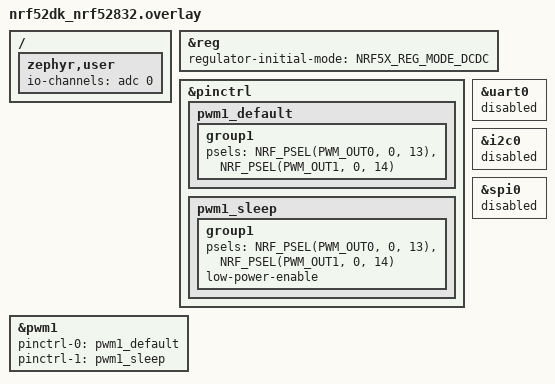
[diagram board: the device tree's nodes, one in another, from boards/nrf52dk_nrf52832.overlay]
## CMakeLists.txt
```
cmake_minimum_required(VERSION 3.20.0)

find_package(Zephyr REQUIRED HINTS $ENV{ZEPHYR_BASE})
project(yuitag)

set(YUITAG_CORE_DIR ${CMAKE_CURRENT_SOURCE_DIR}/../../YuiTagCore)

target_include_directories(app PRIVATE
    ${CMAKE_CURRENT_SOURCE_DIR}/src
    ${YUITAG_CORE_DIR}/include
    ${YUITAG_CORE_DIR}/lib
)

target_sources(app PRIVATE
    src/main.c
    src/app.c
    src/yuitag_platform.c
    src/yuitag_crypto.c
    src/yuitag_buzzer.c
    src/yuitag_ble.c
    src/yuitag_findmy.c
    ${YUITAG_CORE_DIR}/src/yuitag_device.c
    ${YUITAG_CORE_DIR}/src/yuitag_crypto_common.c
    ${YUITAG_CORE_DIR}/src/yuitag_findmy_logic.c
    ${YUITAG_CORE_DIR}/src/yuitag_adv.c
    ${YUITAG_CORE_DIR}/src/yuitag_beep.c
)
```

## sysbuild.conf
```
# Build with MCUboot as the bootloader (NCS sysbuild).
# Overwrite-only mode matches the BG22 in-place OTA behavior:
# the new image overwrites the running image with no rollback.
SB_CONFIG_BOOTLOADER_MCUBOOT=y
SB_CONFIG_MCUBOOT_MODE_OVERWRITE_ONLY=y
SB_CONFIG_MERGED_HEX_FILES=y
```

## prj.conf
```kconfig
# ============================================================
# YuiTag nRF52832 应用工程配置 (Zephyr / NCS)
# ============================================================

# --- 系统与时钟 ---
CONFIG_SYS_CLOCK_TICKS_PER_SEC=1000
CONFIG_MAIN_STACK_SIZE=4096
CONFIG_HEAP_MEM_POOL_SIZE=8192
# 系统工作队列执行 Find My secp224r1 软件 ECC 密钥派生运算，需分配足够栈空间 (4KB)
CONFIG_SYSTEM_WORKQUEUE_STACK_SIZE=4096
CONFIG_PM_DEVICE=y

# --- 蓝牙外设配置 ---
CONFIG_BT=y
CONFIG_BT_PERIPHERAL=y
# 蓝牙 RX 线程负责处理 GATT 回调及协议栈调用链，配置为 4KB 以免溢出
CONFIG_BT_RX_STACK_SIZE=4096
CONFIG_BT_DEVICE_NAME_DYNAMIC=y
CONFIG_BT_DEVICE_NAME_MAX=24
CONFIG_BT_MAX_CONN=1
CONFIG_BT_EXT_ADV=y
CONFIG_BT_EXT_ADV_MAX_ADV_SET=2
CONFIG_BT_ID_MAX=2
CONFIG_BT_BUF_ACL_RX_SIZE=251
CONFIG_BT_BUF_ACL_TX_SIZE=251
CONFIG_BT_L2CAP_TX_MTU=247
CONFIG_BT_ATT_PREPARE_COUNT=8
# 优选连接参数 (由应用层 yuitag_ble_try_conn_param_update 延迟 15 秒温和更新，禁用协议栈自动无条件降速)
CONFIG_BT_GAP_AUTO_UPDATE_CONN_PARAMS=n
CONFIG_BT_PERIPHERAL_PREF_MIN_INT=48
CONFIG_BT_PERIPHERAL_PREF_MAX_INT=72
CONFIG_BT_PERIPHERAL_PREF_LATENCY=0
CONFIG_BT_PERIPHERAL_PREF_TIMEOUT=400

# --- 加密配置 (PSA Crypto + Oberon 纯软实现；nRF52832 无硬件 CC310) ---
CONFIG_PSA_CRYPTO=y
CONFIG_PSA_WANT_GENERATE_RANDOM=y
CONFIG_PSA_WANT_KEY_TYPE_AES=y
CONFIG_PSA_WANT_ALG_CTR=y
CONFIG_PSA_WANT_ALG_ECDH=y
CONFIG_PSA_WANT_ALG_SHA_256=y
CONFIG_PSA_WANT_KEY_TYPE_ECC_KEY_PAIR_GENERATE=y
CONFIG_PSA_WANT_KEY_TYPE_ECC_KEY_PAIR_IMPORT=y
CONFIG_PSA_WANT_KEY_TYPE_ECC_KEY_PAIR_EXPORT=y
CONFIG_PSA_WANT_ECC_SECP_R1_256=y
CONFIG_PSA_WANT_ECC_SECP_R1_224=y

# --- 存储 (NVS) ---
CONFIG_NVS=y
CONFIG_FLASH=y
CONFIG_FLASH_MAP=y
CONFIG_FLASH_PAGE_LAYOUT=y
CONFIG_MPU_ALLOW_FLASH_WRITE=y

# --- PWM (无源蜂鸣器) ---
CONFIG_PWM=y

# --- ADC (SAADC 电池分压与供电电压测量) ---
CONFIG_ADC=y

# --- 控制台与日志 (SEGGER RTT) ---
CONFIG_CONSOLE=y
CONFIG_USE_SEGGER_RTT=y
CONFIG_RTT_CONSOLE=y
CONFIG_UART_CONSOLE=n

# --- OTA DFU (基于 BLE 的 MCUmgr SMP 协议，静态注册 + 应用层安全鉴权 Hook) ---
CONFIG_NET_BUF=y
CONFIG_ZCBOR=y
CONFIG_CRC=y
CONFIG_MCUMGR=y
CONFIG_MCUMGR_TRANSPORT_BT=y
CONFIG_MCUMGR_GRP_IMG=y
CONFIG_MCUMGR_GRP_OS=y
CONFIG_IMG_MANAGER=y
CONFIG_IMG_ENABLE_IMAGE_CHECK=y
CONFIG_STREAM_FLASH=y
CONFIG_MCUMGR_MGMT_NOTIFICATION_HOOKS=y
CONFIG_MCUMGR_SMP_COMMAND_STATUS_HOOKS=y

# 全局发射功率 (dBm)，nRF52832 最大硬件功率为 +4 dBm
CONFIG_BT_CTLR_TX_PWR_ANTENNA=4

# 允许运行时通过 Vendor-Specific HCI 指令动态调节发射功率
CONFIG_BT_HCI_VS=y
CONFIG_BT_CTLR_TX_PWR_DYNAMIC_CONTROL=y
```

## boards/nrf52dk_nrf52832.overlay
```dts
/*
 * YuiTag nRF52 DK overlay:
 * PWM1 drives the piezo buzzer differentially on P0.13 (OUT0) / P0.14 (OUT1).
 * Channel polarity is set in code (OUT1 inverted).
 * SAADC channel 0 measures VDD (supply rail) for battery estimation.
 */

#include <zephyr/dt-bindings/regulator/nrf5x.h>

/ {
	zephyr,user {
		io-channels = <&adc 0>;
	};
};

/* Enable SoC internal DC/DC converter */
&reg {
	regulator-initial-mode = <NRF5X_REG_MODE_DCDC>;
};

&pinctrl {
	pwm1_default: pwm1_default {
		group1 {
			psels = <NRF_PSEL(PWM_OUT0, 0, 13)>,
				<NRF_PSEL(PWM_OUT1, 0, 14)>;
		};
	};

	pwm1_sleep: pwm1_sleep {
		group1 {
			psels = <NRF_PSEL(PWM_OUT0, 0, 13)>,
				<NRF_PSEL(PWM_OUT1, 0, 14)>;
			low-power-enable;
		};
	};
};

&pwm1 {
	status = "okay";
	pinctrl-0 = <&pwm1_default>;
	pinctrl-1 = <&pwm1_sleep>;
	pinctrl-names = "default", "sleep";
};

&uart0 {
	status = "disabled";
};

&i2c0 {
	status = "disabled";
};

&spi0 {
	status = "disabled";
};
```

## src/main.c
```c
/* ============================================================
 * YuiTag 主程序入口 (nRF52832 / Zephyr RTOS)
 * ============================================================ */

#include <zephyr/kernel.h>
#include <zephyr/bluetooth/bluetooth.h>

#include "yuitag_config.h"
#include "yuitag_platform.h"
#include "yuitag_crypto.h"
#include "yuitag_device.h"
#include "yuitag_buzzer_types.h"
#include "yuitag_ble.h"
#include "app.h"

#ifndef IS_SPARKS
#include "yuitag_findmy.h"
#endif

static YuiTagDevice g_dev;

static void bt_ready(int err)
{
    if (err) {
        platform_log("[BT] enable failed: %d", err);
        return;
    }

    platform_log("[BT] Ready");

    uint8_t mac[6];
    platform_get_mac(mac);
    yuitag_device_init(&g_dev, mac);

    /* 连续断电重启检测 (恢复出厂设置)；置于 device_init 之后以确保重置名称包含有效 shortUid */
    bool resetTriggered = yuitag_device_power_cycle_check(&g_dev);

    if (!resetTriggered) {
        yuitag_beep_startup();
    }

    yuitag_ble_set_device_name(g_dev.deviceName);
    yuitag_ble_update_dis_values(&g_dev);
    yuitag_ble_update_param_value(&g_dev);

    yuitag_ble_update_advertising(&g_dev, true);

#ifndef IS_SPARKS
    yuitag_findmy_init();
    yuitag_ble_update_param_value(&g_dev);
    if (g_dev.findmyEnabled) {
        if (!yuitag_findmy_enable()) {
            g_dev.findmyEnabled = false;
            platform_log("[FINDMY] Enable failed at boot, reverting flag");
            yuitag_ble_update_param_value(&g_dev);
        } else {
            yuitag_findmy_update_battery(g_dev.batteryLevel);
        }
    }
#endif

    app_mark_initialized();
    platform_log("[BOOT] YuiTag initialized");
}

int main(void)
{
    platform_init();
    yuitag_crypto_init();
    app_init(&g_dev);
    yuitag_ble_init(&g_dev);

    int err = bt_enable(bt_ready);
    if (err) {
        platform_log("[BT] bt_enable failed: %d", err);
    }

    while (1) {
        k_sleep(K_FOREVER);
    }
    return 0;
}
```

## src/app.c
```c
/* ============================================================
 * YuiTag 应用调度层实现 (延时工作队列与周期定时器)
 * ============================================================ */

#include "app.h"
#include "yuitag_platform.h"
#include "yuitag_ble.h"

#ifndef IS_SPARKS
#include "yuitag_findmy.h"
#endif

#include <zephyr/kernel.h>

#if defined(CONFIG_MCUMGR_SMP_COMMAND_STATUS_HOOKS)
#include <zephyr/mgmt/mcumgr/mgmt/callbacks.h>
#endif

static YuiTagDevice *g_dev;
static bool g_initialized = false;

static struct k_work s_process_work;
static struct k_timer s_periodic_timer;

#if defined(CONFIG_MCUMGR_SMP_COMMAND_STATUS_HOOKS)
/* ------------------------------------------------------------
 * MCUmgr SMP 指令接收安全拦截回调 (仅在 0x6F 授权后放行)
 * ------------------------------------------------------------ */
static enum mgmt_cb_return smp_cmd_recv_callback(uint32_t event, enum mgmt_cb_return prev_status,
                                                  int32_t *rc, uint16_t *group, bool *abort_more,
                                                  void *data, size_t data_size)
{
    (void)event; (void)prev_status; (void)group; (void)abort_more; (void)data; (void)data_size;
    if (!app_is_ota_authorized()) {
        platform_log("[OTA-SEC] SMP command rejected: unauthorized");
        *rc = 2; /* MGMT_ERR_EACCESS (Access denied) */
        return MGMT_CB_ERROR_RC;
    }
    return MGMT_CB_OK;
}

static struct mgmt_callback s_smp_cb = {
    .callback = smp_cmd_recv_callback,
    .event_id = MGMT_EVT_OP_CMD_RECV,
};
#endif

static void process_action_handler(struct k_work *work);

/* ------------------------------------------------------------
 * 主任务事件处理 (工作队列回调)
 * ------------------------------------------------------------ */
static void process_action_handler(struct k_work *work)
{
    (void)work;
    if (!g_initialized || !g_dev) {
        return;
    }

    yuitag_device_process_events(g_dev);
}

static void periodic_timer_handler(struct k_timer *timer)
{
    (void)timer;
    app_proceed();
}

/* ------------------------------------------------------------
 * 模块初始化
 * ------------------------------------------------------------ */
void app_init(YuiTagDevice *dev)
{
    g_dev = dev;

    k_work_init(&s_process_work, process_action_handler);
    k_timer_init(&s_periodic_timer, periodic_timer_handler, NULL);
    k_timer_start(&s_periodic_timer,
                  K_SECONDS(PERIODIC_CHECK_INTERVAL_MS / 1000),
                  K_SECONDS(PERIODIC_CHECK_INTERVAL_MS / 1000));

#if defined(CONFIG_MCUMGR_SMP_COMMAND_STATUS_HOOKS)
    mgmt_callback_register(&s_smp_cb);
#endif
}

void app_proceed(void)
{
    k_work_submit(&s_process_work);
}

void app_mark_initialized(void)
{
    g_initialized = true;
    app_proceed();
}

/* ------------------------------------------------------------
 * OTA 授权状态管理
 * ------------------------------------------------------------ */
void app_ota_authorize(void)
{
    if (g_dev) {
        g_dev->otaAuthorized = true;
    }
    platform_log("[OTA] Authorized");
    yuitag_ble_set_fast_conn_params();
}

void app_ota_deauthorize(void)
{
    if (g_dev) {
        g_dev->otaAuthorized = false;
    }
    platform_log("[OTA] Deauthorized");
}

bool app_is_ota_authorized(void)
{
    return (g_dev && g_dev->otaAuthorized);
}
```

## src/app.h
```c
#ifndef APP_H
#define APP_H

/* ============================================================
 * YuiTag 应用层调度接口 (工作队列与周期定时器)
 * ============================================================ */

#include "yuitag_device.h"
#include <stdbool.h>

/* 初始化工作队列及周期定时器 */
void app_init(YuiTagDevice *dev);

/* 触发应用事件处理 (可在 ISR 或 BLE 回调中调用) */
void app_proceed(void);

/* 标记应用就绪 (在蓝牙就绪及设备初始化完成后调用) */
void app_mark_initialized(void);

/* OTA DFU 授权状态管理 (由 CMD_OTA_AUTHORIZE 激活，断开连接时清除) */
void app_ota_authorize(void);
void app_ota_deauthorize(void);
bool app_is_ota_authorized(void);

#endif /* APP_H */
```

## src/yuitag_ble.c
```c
// ============================================================
// YuiTag BLE 协议栈实现 - Zephyr Bluetooth Host
// ============================================================

#include "yuitag_ble.h"
#include "yuitag_crypto.h"
#include "yuitag_platform.h"
#include "yuitag_adv.h"
#include "app.h"

#include <zephyr/bluetooth/bluetooth.h>
#include <zephyr/bluetooth/gatt.h>
#include <zephyr/bluetooth/uuid.h>
#include <zephyr/bluetooth/conn.h>
#include <zephyr/sys/byteorder.h>
#include <zephyr/sys/util.h>
#include <zephyr/kernel.h>

#include <string.h>

#ifndef IS_SPARKS
#include "yuitag_findmy.h"
#endif

// ============================================================
// 自定义 128 位 UUID (基准: 722Axxxx-8a74-432f-9055-7ed8a5584a11)
// ============================================================
#define YUITAG_UUID_SVC   BT_UUID_DECLARE_128(BT_UUID_128_ENCODE(0x722aaa00, 0x8a74, 0x432f, 0x9055, 0x7ed8a5584a11))
#define YUITAG_UUID_BIND  BT_UUID_DECLARE_128(BT_UUID_128_ENCODE(0x722aaa42, 0x8a74, 0x432f, 0x9055, 0x7ed8a5584a11))
#define YUITAG_UUID_CMD   BT_UUID_DECLARE_128(BT_UUID_128_ENCODE(0x722aaa43, 0x8a74, 0x432f, 0x9055, 0x7ed8a5584a11))
#define YUITAG_UUID_PARAM BT_UUID_DECLARE_128(BT_UUID_128_ENCODE(0x722aaa46, 0x8a74, 0x432f, 0x9055, 0x7ed8a5584a11))

// ============================================================
// 模块内部状态
// ============================================================
static YuiTagDevice *g_dev;
static struct bt_conn *g_conn;
static bool g_connected = false;
static bool g_cccd_bind = false;
static bool g_cccd_cmd  = false;
static bool g_cccd_param = false;
static bool g_adv_failed = false;

static uint32_t g_conn_start_ms = 0;
static bool g_conn_param_updated = false;
static struct k_work_delayable s_conn_param_work;
static void conn_param_work_handler(struct k_work *work);

static struct k_work_delayable s_adv_refresh_work;
static void adv_refresh_work_handler(struct k_work *work)
{
    (void)work;
    if (g_dev) {
        yuitag_ble_update_advertising(g_dev, true);
        app_proceed();
    }
}

// 专用绑定加密工作队列 (4096 字节栈空间)
// ECDH 软件计算栈开销较大，移至独立线程处理，避免在 BLE RX 线程触发栈溢出
#define BIND_CRYPTO_STACK_SIZE 4096
static K_THREAD_STACK_DEFINE(s_bind_crypto_stack, BIND_CRYPTO_STACK_SIZE);
static struct k_work_q s_bind_crypto_wq;
static struct k_work s_bind_crypto_work;
static uint8_t s_peer_pubkey[ECDH_PUBKEY_LEN];

// ============================================================
// CCCD 特征通知使能状态变更回调
// ============================================================
static void ccc_bind_changed(const struct bt_gatt_attr *attr, uint16_t value)
{
    (void)attr;
    g_cccd_bind = (value == BT_GATT_CCC_NOTIFY);
    platform_log("[GATT] CCC bind notif=%d", g_cccd_bind);
}

static void ccc_cmd_changed(const struct bt_gatt_attr *attr, uint16_t value)
{
    (void)attr;
    g_cccd_cmd = (value == BT_GATT_CCC_NOTIFY);
    platform_log("[GATT] CCC cmd notif=%d", g_cccd_cmd);
}

static void ccc_param_changed(const struct bt_gatt_attr *attr, uint16_t value)
{
    (void)attr;
    g_cccd_param = (value == BT_GATT_CCC_NOTIFY);
    platform_log("[GATT] CCC param notif=%d", g_cccd_param);
}

// ============================================================
// 特征通知发送辅助函数
// ============================================================
static void notify_by_uuid(const struct bt_uuid *uuid,
                           const uint8_t *data, size_t len)
{
    if (!g_conn) {
        return;
    }

    bool ccc_enabled;
    if (!bt_uuid_cmp(uuid, YUITAG_UUID_BIND)) {
        ccc_enabled = g_cccd_bind;
    } else if (!bt_uuid_cmp(uuid, YUITAG_UUID_CMD)) {
        ccc_enabled = g_cccd_cmd;
    } else if (!bt_uuid_cmp(uuid, YUITAG_UUID_PARAM)) {
        ccc_enabled = g_cccd_param;
    } else {
        return;
    }

    if (!ccc_enabled) {
        return;
    }

    uint16_t mtu = bt_gatt_get_mtu(g_conn);
    if (len > (size_t)(mtu - 3)) {
        return;
    }

    struct bt_gatt_notify_params params = {
        .uuid = uuid,
        .attr = NULL,
        .data = data,
        .len = (uint16_t)len,
        .func = NULL,
        .user_data = NULL,
    };
    bt_gatt_notify_cb(g_conn, &params);
}

static void send_notify_by_ch(yuitag_notify_ch_t ch, const uint8_t *data, size_t len)
{
    switch (ch) {
    case YUITAG_NOTIFY_BIND:
        notify_by_uuid(YUITAG_UUID_BIND, data, len);
        break;
    case YUITAG_NOTIFY_CMD:
        notify_by_uuid(YUITAG_UUID_CMD, data, len);
        break;
    case YUITAG_NOTIFY_PARAM:
        notify_by_uuid(YUITAG_UUID_PARAM, data, len);
        break;
    default:
        break;
    }
}

// ============================================================
// 绑定协商加密任务处理 (独立大栈工作队列线程)
// ============================================================
static void bind_crypto_work_handler(struct k_work *work)
{
    (void)work;

    if (!g_conn) {
        g_dev->pendingBindAbort = true;
        app_proceed();
        return;
    }

    uint8_t tagPubKey[ECDH_PUBKEY_LEN];
    size_t pubKeyLen = 0;

    if (!yuitag_device_bind_process_peer_key(g_dev, s_peer_pubkey, ECDH_PUBKEY_LEN,
                                              tagPubKey, &pubKeyLen)) {
        uint8_t fail = STATUS_FAILED;
        notify_by_uuid(YUITAG_UUID_BIND, &fail, 1);
        g_dev->pendingBindAbort = true;
        app_proceed();
        return;
    }

    if (pubKeyLen > (size_t)(bt_gatt_get_mtu(g_conn) - 3)) {
        platform_log("[BIND] MTU too small for pubkey (%d bytes, MTU=%u)",
                     pubKeyLen, bt_gatt_get_mtu(g_conn));
        g_dev->pendingBindAbort = true;
        app_proceed();
        return;
    }

    notify_by_uuid(YUITAG_UUID_BIND, tagPubKey, pubKeyLen);
    platform_log("[BIND] Sent Tag pubkey (%d bytes)", pubKeyLen);
}

// ============================================================
// GATT 读特征回调 (DIS 设备信息与参数通道)
// ============================================================
static ssize_t read_dis_string(struct bt_conn *conn,
                               const struct bt_gatt_attr *attr,
                               void *buf, uint16_t len, uint16_t offset)
{
    const char *str = (const char *)attr->user_data;
    return bt_gatt_attr_read(conn, attr, buf, len, offset, str, strlen(str));
}

static ssize_t read_param(struct bt_conn *conn,
                          const struct bt_gatt_attr *attr,
                          void *buf, uint16_t len, uint16_t offset)
{
    uint8_t paramBuf[PARAM_DECRYPT_BUF_MAX_LEN];
    size_t paramLen = yuitag_device_param_read(g_dev, paramBuf, sizeof(paramBuf));
    if (paramLen == 0) {
        return BT_GATT_ERR(BT_ATT_ERR_UNLIKELY);
    }
    return bt_gatt_attr_read(conn, attr, buf, len, offset, paramBuf, paramLen);
}

// ============================================================
// GATT 写特征回调
// ============================================================
static ssize_t write_bind(struct bt_conn *conn, const struct bt_gatt_attr *attr,
                          const void *buf, uint16_t len, uint16_t offset, uint8_t flags)
{
    (void)conn; (void)attr; (void)offset; (void)flags;

    if (g_dev->isBound) {
        platform_log("[BIND] Ignored: already bound");
        return len;
    }

    if (g_dev->waitingVerify) {
        platform_log("[BIND] Ignored: bind already in progress");
        return len;
    }

    if (len != ECDH_PUBKEY_LEN || ((const uint8_t *)buf)[0] != 0x04) {
        platform_log("[BIND] Invalid pubkey format (len=%d, fmt=0x%02X)",
                     len, len > 0 ? ((const uint8_t *)buf)[0] : 0x00);
        uint8_t fail = STATUS_FAILED;
        notify_by_uuid(YUITAG_UUID_BIND, &fail, 1);
        g_dev->pendingBindAbort = true;
        app_proceed();
        return len;
    }

    // 标记绑定中，将 ECDH 计算提交至大栈独立工作队列执行
    g_dev->waitingVerify = true;
    memcpy(s_peer_pubkey, buf, ECDH_PUBKEY_LEN);
    k_work_submit_to_queue(&s_bind_crypto_wq, &s_bind_crypto_work);
    return len;
}

static ssize_t write_cmd(struct bt_conn *conn, const struct bt_gatt_attr *attr,
                         const void *buf, uint16_t len, uint16_t offset, uint8_t flags)
{
    (void)conn; (void)attr; (void)offset; (void)flags;

    yuitag_response_t resp = {0};
    yuitag_device_handle_cmd_write(g_dev, buf, len, &resp);

    if (resp.channel != YUITAG_NOTIFY_NONE) {
        send_notify_by_ch(resp.channel, resp.data, resp.len);
    }

    if (g_dev->pendingConnParamReset) {
        g_dev->pendingConnParamReset = false;
        yuitag_ble_update_dis_values(g_dev);
        g_conn_param_updated = false;
        k_work_reschedule(&s_conn_param_work, K_MSEC(CONN_PARAM_DELAY_MS));
    }

    if (g_dev->pendingUnbindClear || g_dev->pendingAdvRefresh || g_dev->pendingBindAbort) {
        app_proceed();
    }

    return len;
}

static ssize_t write_param(struct bt_conn *conn, const struct bt_gatt_attr *attr,
                           const void *buf, uint16_t len, uint16_t offset, uint8_t flags)
{
    (void)conn; (void)attr; (void)offset; (void)flags;

    yuitag_response_t resp = {0};
    yuitag_device_handle_param_write(g_dev, buf, len, &resp);

    if (resp.channel != YUITAG_NOTIFY_NONE) {
        send_notify_by_ch(resp.channel, resp.data, resp.len);
    }

    if (g_dev->pendingParamSave || g_dev->pendingAdvRefresh) {
        app_proceed();
    }
    yuitag_ble_update_param_value(g_dev);

    return len;
}

// ============================================================
// GATT Service Definition
// ============================================================

static ssize_t read_serial(struct bt_conn *conn,
                           const struct bt_gatt_attr *attr,
                           void *buf, uint16_t len, uint16_t offset);

static ssize_t read_system_id(struct bt_conn *conn,
                              const struct bt_gatt_attr *attr,
                              void *buf, uint16_t len, uint16_t offset);

/* 设备信息服务 (DIS, 0x180A) */
BT_GATT_SERVICE_DEFINE(dis_svc,
    BT_GATT_PRIMARY_SERVICE(BT_UUID_DIS),
    BT_GATT_CHARACTERISTIC(BT_UUID_DECLARE_16(0x2A29),
        BT_GATT_CHRC_READ, BT_GATT_PERM_READ, read_dis_string, NULL, (void *)MANUFACTURER),
    BT_GATT_CHARACTERISTIC(BT_UUID_DECLARE_16(0x2A24),
        BT_GATT_CHRC_READ, BT_GATT_PERM_READ, read_dis_string, NULL, (void *)MODEL_NUMBER),
    BT_GATT_CHARACTERISTIC(BT_UUID_DECLARE_16(0x2A25),
        BT_GATT_CHRC_READ, BT_GATT_PERM_READ, read_serial, NULL, NULL),
    BT_GATT_CHARACTERISTIC(BT_UUID_DECLARE_16(0x2A23),
        BT_GATT_CHRC_READ, BT_GATT_PERM_READ, read_system_id, NULL, NULL),
    BT_GATT_CHARACTERISTIC(BT_UUID_DECLARE_16(0x2A27),
        BT_GATT_CHRC_READ, BT_GATT_PERM_READ, read_dis_string, NULL, (void *)HW_VERSION),
    BT_GATT_CHARACTERISTIC(BT_UUID_DECLARE_16(0x2A26),
        BT_GATT_CHRC_READ, BT_GATT_PERM_READ, read_dis_string, NULL, (void *)FW_VERSION),
    BT_GATT_CHARACTERISTIC(BT_UUID_DECLARE_16(0x2A28),
        BT_GATT_CHRC_READ, BT_GATT_PERM_READ, read_dis_string, NULL, (void *)YUITAG_CORE_VERSION),
);

/* YuiTag 核心服务 (722aaa00-...) */
BT_GATT_SERVICE_DEFINE(yuitag_core_svc,
    BT_GATT_PRIMARY_SERVICE(YUITAG_UUID_SVC),

    BT_GATT_CHARACTERISTIC(YUITAG_UUID_BIND,
        BT_GATT_CHRC_WRITE | BT_GATT_CHRC_NOTIFY,
        BT_GATT_PERM_WRITE, NULL, write_bind, NULL),
    BT_GATT_CCC(ccc_bind_changed, BT_GATT_PERM_READ | BT_GATT_PERM_WRITE),

    BT_GATT_CHARACTERISTIC(YUITAG_UUID_CMD,
        BT_GATT_CHRC_WRITE | BT_GATT_CHRC_NOTIFY,
        BT_GATT_PERM_WRITE, NULL, write_cmd, NULL),
    BT_GATT_CCC(ccc_cmd_changed, BT_GATT_PERM_READ | BT_GATT_PERM_WRITE),

    BT_GATT_CHARACTERISTIC(YUITAG_UUID_PARAM,
        BT_GATT_CHRC_READ | BT_GATT_CHRC_WRITE | BT_GATT_CHRC_NOTIFY,
        BT_GATT_PERM_READ | BT_GATT_PERM_WRITE, read_param, write_param, NULL),
    BT_GATT_CCC(ccc_param_changed, BT_GATT_PERM_READ | BT_GATT_PERM_WRITE),
);

/* ------------------------------------------------------------
 * DIS 特征值动态读取
 * ------------------------------------------------------------ */
static ssize_t read_serial(struct bt_conn *conn,
                           const struct bt_gatt_attr *attr,
                           void *buf, uint16_t len, uint16_t offset)
{
    if (!g_dev) {
        return BT_GATT_ERR(BT_ATT_ERR_UNLIKELY);
    }
    return bt_gatt_attr_read(conn, attr, buf, len, offset,
                             g_dev->serial, strlen(g_dev->serial));
}

static ssize_t read_system_id(struct bt_conn *conn,
                              const struct bt_gatt_attr *attr,
                              void *buf, uint16_t len, uint16_t offset)
{
    /* 生成 8 字节 Bluetooth System ID (EUI-64, 构造逻辑在 YuiTagCore) */
    uint8_t mac[6];
    uint8_t sid[8];

    platform_get_mac(mac);
    yuitag_crypto_make_system_id(mac, sid);

    return bt_gatt_attr_read(conn, attr, buf, len, offset, sid, sizeof(sid));
}

/* ------------------------------------------------------------
 * 广播控制与发射功率调节
 * ------------------------------------------------------------ */
#include <zephyr/bluetooth/hci.h>
#if defined(CONFIG_BT_HCI_VS) || defined(CONFIG_BT_CTLR) || defined(CONFIG_BT_LL_SOFTDEVICE)
#include <zephyr/bluetooth/hci_vs.h>
#endif

static void set_adv_tx_power(int8_t power_dbm)
{
    int8_t valid_powers[] = { 4, 3, 0, -4, -8, -12, -16, -20, -40 };
    int8_t selected = -40;
    for (size_t i = 0; i < ARRAY_SIZE(valid_powers); i++) {
        if (power_dbm >= valid_powers[i]) {
            selected = valid_powers[i];
            break;
        }
    }

#if defined(BT_HCI_OP_VS_WRITE_TX_POWER_LEVEL)
    struct bt_hci_cp_vs_write_tx_power_level *cp;
    struct net_buf *buf, *rsp = NULL;

    buf = bt_hci_cmd_alloc(K_FOREVER);
    if (buf) {
        cp = net_buf_add(buf, sizeof(*cp));
        cp->handle_type = BT_HCI_VS_LL_HANDLE_TYPE_ADV;
        cp->handle = sys_cpu_to_le16(0);
        cp->tx_power_level = selected;

        int err = bt_hci_cmd_send_sync(BT_HCI_OP_VS_WRITE_TX_POWER_LEVEL, buf, &rsp);
        if (err) {
            platform_log("[ADV] Set TX power (%d dBm) failed: %d", selected, err);
        } else {
            int8_t actual = selected;
            if (rsp && rsp->len >= sizeof(struct bt_hci_rp_vs_write_tx_power_level)) {
                struct bt_hci_rp_vs_write_tx_power_level *rp = (void *)rsp->data;
                actual = rp->selected_tx_power;
            }
            platform_log("[ADV] Set TX power: %d dBm (actual: %d dBm)", selected, actual);
        }
        if (rsp) {
            net_buf_unref(rsp);
        }
    }
#else
    ARG_UNUSED(selected);
#endif
}

/* 字段布局由 YuiTagCore yuitag_adv 统一构造, 此处仅映射至 Zephyr bt_data */
static void start_advertising(YuiTagDevice *dev, bool connectable)
{
    /* 主广播包字段段 (flags + 厂商数据 + [绑定后]电量 + [debug]诊断) */
    uint8_t adStorage[32];
    yuitag_adv_seg_t adSegs[4];
    size_t adSegCount = yuitag_adv_build(dev, adSegs, ARRAY_SIZE(adSegs),
                                         adStorage, sizeof(adStorage));
    if (adSegCount == 0) {
        platform_log("[ADV] Failed to build adv data");
        g_adv_failed = true;
        return;
    }

    struct bt_data ad[4];
    size_t adLen = 0;
    for (size_t i = 0; i < adSegCount && adLen < ARRAY_SIZE(ad); i++) {
        ad[adLen].type = adSegs[i].type;
        ad[adLen].data_len = adSegs[i].len;
        ad[adLen].data = adSegs[i].data;
        adLen++;
    }

    /* 扫描响应包: 完整设备名称 */
    uint8_t sdStorage[DEVICE_NAME_MAX_LEN + 1];
    yuitag_adv_seg_t sdSegs[1];
    size_t sdSegCount = yuitag_adv_build_scan_rsp(dev, sdSegs, ARRAY_SIZE(sdSegs),
                                                  sdStorage, sizeof(sdStorage));

    struct bt_data sd[1];
    size_t sdLen = 0;
    if (sdSegCount == 1) {
        sd[0].type = sdSegs[0].type;
        sd[0].data_len = sdSegs[0].len;
        sd[0].data = sdSegs[0].data;
        sdLen = 1;
    }

    uint32_t units = ((uint32_t)dev->advInterval * 8U) / 5U;
    uint32_t opt = BT_LE_ADV_OPT_USE_IDENTITY;
    opt |= connectable ? BT_LE_ADV_OPT_CONN : BT_LE_ADV_OPT_SCANNABLE;
    struct bt_le_adv_param param = BT_LE_ADV_PARAM_INIT(opt, units, units, NULL);

    int err = bt_le_adv_start(&param, ad, adLen, sd, sdLen);
    if (err) {
        platform_log("[ADV] Start failed: %d", err);
        g_adv_failed = true;
        return;
    }

    set_adv_tx_power(dev->txPower);

    g_adv_failed = false;
    platform_log("[ADV] Mode=%s connectable=%d interval=%dms txPower=%d",
                 dev->isBound ? "Normal" : "Initial", connectable, dev->advInterval, dev->txPower);
}

void yuitag_ble_update_advertising(YuiTagDevice *dev, bool rebuild_data)
{
    (void)rebuild_data;
    bt_le_adv_stop();
    start_advertising(dev, !g_connected);
}

bool yuitag_ble_adv_failed(void)
{
    return g_adv_failed;
}

void yuitag_ble_disconnect(void)
{
    if (g_conn) {
        bt_conn_disconnect(g_conn, BT_HCI_ERR_REMOTE_USER_TERM_CONN);
    }
}

bool yuitag_ble_is_connected(void)
{
    return g_connected;
}

/* ------------------------------------------------------------
 * GATT 属性更新
 * ------------------------------------------------------------ */
void yuitag_ble_update_param_value(YuiTagDevice *dev)
{
    /* 参数通道在 read_param 回调中动态生成，无需主动更新缓存 */
    (void)dev;
}

void yuitag_ble_update_dis_values(YuiTagDevice *dev)
{
    /* 解绑或重置设备名称后，同步更新 Zephyr GAP 设备名 */
    bt_set_name(dev->deviceName);
}

void yuitag_ble_set_device_name(const char *name)
{
    bt_set_name(name);
}

/* ------------------------------------------------------------
 * 连接状态回调
 * ------------------------------------------------------------ */
static void connected(struct bt_conn *conn, uint8_t err)
{
    if (err) {
        platform_log("[CONN] Connect failed: %u", err);
        return;
    }

    g_conn = bt_conn_ref(conn);
    g_connected = true;
    g_conn_start_ms = platform_millis();
    g_conn_param_updated = false;
    g_cccd_bind = g_cccd_cmd = g_cccd_param = false;

    yuitag_device_on_connected(g_dev);

    /* 已绑定状态下，延时 15.0 秒申请温和降速连接参数 (预留充裕窗口给服务发现与 OTA 授权，授权后不降速) */
    if (g_dev && g_dev->isBound) {
        k_work_reschedule(&s_conn_param_work, K_MSEC(CONN_PARAM_DELAY_MS));
    }

    /* 连接建立后延迟 30ms 重新配置不可连接广播，避开 BT_RX 协议栈清理竞态 */
    k_work_reschedule(&s_adv_refresh_work, K_MSEC(30));

    platform_log("[CONN] Connected");
}

static void disconnected(struct bt_conn *conn, uint8_t reason)
{
    (void)reason;
    k_work_cancel_delayable(&s_conn_param_work);

    if (g_conn) {
        bt_conn_unref(g_conn);
        g_conn = NULL;
    }
    g_connected = false;
    g_cccd_bind = g_cccd_cmd = g_cccd_param = false;

    yuitag_device_on_disconnected(g_dev);
    app_proceed();

    /* 断开后延迟 30ms 恢复常态可连接广播，避开 BT_RX 协议栈清理竞态 */
    k_work_reschedule(&s_adv_refresh_work, K_MSEC(30));
    platform_log("[CONN] Disconnected (reason 0x%02x)", reason);
}

BT_CONN_CB_DEFINE(conn_callbacks) = {
    .connected = connected,
    .disconnected = disconnected,
};

/* ------------------------------------------------------------
 * 延时连接参数更新
 * ------------------------------------------------------------ */
static void conn_param_work_handler(struct k_work *work)
{
    (void)work;
    if (g_dev) {
        yuitag_ble_try_conn_param_update(g_dev);
    }
}

void yuitag_ble_try_conn_param_update(YuiTagDevice *dev)
{
    if (!g_connected || g_conn_param_updated || !g_conn) {
        return;
    }
    if (!dev || !dev->isBound) {
        return;
    }
    if (platform_millis() - g_conn_start_ms < CONN_PARAM_DELAY_MS) {
        return;
    }
    if (app_is_ota_authorized()) {
        return;
    }

    /* 平衡功耗与响应的温和降速参数:
     * 1. 间隔 60ms ~ 90ms (48 ~ 72 * 1.25ms)，保证双向低延迟与高响应度
     * 2. 从机延迟 0 (禁止跳过事件，彻底杜绝超时与交互卡顿)
     * 3. 监控超时 4000ms (400 * 10ms)
     */
    struct bt_le_conn_param param = {
        .interval_min = CONN_PARAM_INTERVAL_MIN_UNITS,
        .interval_max = CONN_PARAM_INTERVAL_MAX_UNITS,
        .latency = CONN_PARAM_LATENCY,
        .timeout = CONN_PARAM_TIMEOUT_UNITS,
    };
    int err = bt_conn_le_param_update(g_conn, &param);
    if (err == 0) {
        g_conn_param_updated = true;
        platform_log("[CONN] Balanced param update requested: 60-90ms, lat=0, to=4s");
    } else {
        platform_log("[CONN] Param update failed: %d", err);
    }
}

void yuitag_ble_set_fast_conn_params(void)
{
    if (!g_connected || !g_conn) {
        return;
    }
    /* OTA 高速传输参数: 15ms~30ms, 延迟 0, 超时 4s */
    struct bt_le_conn_param param = {
        .interval_min = CONN_PARAM_FAST_INTERVAL_MIN_UNITS,
        .interval_max = CONN_PARAM_FAST_INTERVAL_MAX_UNITS,
        .latency = CONN_PARAM_LATENCY,
        .timeout = CONN_PARAM_TIMEOUT_UNITS,
    };
    int err = bt_conn_le_param_update(g_conn, &param);
    if (err == 0) {
        g_conn_param_updated = true;
        platform_log("[CONN] Fast param update requested for OTA: 15-30ms, lat=0");
    } else {
        platform_log("[CONN] Fast param update failed: %d", err);
    }
}

/* ------------------------------------------------------------
 * 模块初始化
 * ------------------------------------------------------------ */
void yuitag_ble_init(YuiTagDevice *dev)
{
    g_dev = dev;

    k_work_init_delayable(&s_conn_param_work, conn_param_work_handler);
    k_work_init_delayable(&s_adv_refresh_work, adv_refresh_work_handler);

    k_work_queue_init(&s_bind_crypto_wq);
    k_work_queue_start(&s_bind_crypto_wq, s_bind_crypto_stack,
                       K_THREAD_STACK_SIZEOF(s_bind_crypto_stack),
                       K_PRIO_PREEMPT(10), NULL);
    k_work_init(&s_bind_crypto_work, bind_crypto_work_handler);
}
```

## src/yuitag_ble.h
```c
#ifndef YUITAG_BLE_H
#define YUITAG_BLE_H
// ============================================================
// YuiTag BLE 协议栈接口 - Zephyr Bluetooth Host
// 处理: BLE 广播、GATT 服务与特征、通知推送、连接参数协商
// ============================================================

#include <zephyr/bluetooth/bluetooth.h>
#include "yuitag_device.h"
#include <stdbool.h>

// 初始化 GATT 服务数据库与连接回调 (需在 bt_enable 之前调用)
void yuitag_ble_init(YuiTagDevice *dev);

// 更新广播数据包并重启广播
void yuitag_ble_update_advertising(YuiTagDevice *dev, bool rebuild_data);

void yuitag_ble_disconnect(void);
bool yuitag_ble_is_connected(void);
bool yuitag_ble_adv_failed(void);

void yuitag_ble_update_param_value(YuiTagDevice *dev);
void yuitag_ble_update_dis_values(YuiTagDevice *dev);
void yuitag_ble_set_device_name(const char *name);

// 尝试向主机申请更新连接参数 (符合 Apple 规范)
void yuitag_ble_try_conn_param_update(YuiTagDevice *dev);

// 主动向主机申请快速连接参数 (15ms 间隔，从机延迟 0，供 OTA 高速传输)
void yuitag_ble_set_fast_conn_params(void);

#endif // YUITAG_BLE_H
```

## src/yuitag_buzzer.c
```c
// ============================================================
// YuiTag 蜂鸣器驱动实现 - nRF52832 / Zephyr PWM
// 采用双路互补 PWM 差分驱动压电陶瓷蜂鸣器
// 通道 0 正相，通道 1 反相 (相位差 180 度)
// ============================================================

#include "yuitag_buzzer.h"

#include <zephyr/kernel.h>
#include <zephyr/device.h>
#include <zephyr/devicetree.h>
#include <zephyr/drivers/pwm.h>
#if defined(CONFIG_PM_DEVICE)
#include <zephyr/pm/device.h>
#endif

#define BUZZER_NODE      DT_NODELABEL(pwm1)
#define BUZZER_DEV       DEVICE_DT_GET(BUZZER_NODE)
#define BUZZER_CH_P      0
#define BUZZER_CH_N      1

#define BUZZER_DEFAULT_FREQ     4000U
#define BUZZER_DEFAULT_VOLUME   100U
// nRF52832 PWM 时钟频率 (HFCLK 16MHz)
#define BUZZER_TIMER_CLOCK_HZ   16000000U

static bool s_buzzer_on;
static uint32_t s_freq = BUZZER_DEFAULT_FREQ;
static uint8_t  s_volume_pct = BUZZER_DEFAULT_VOLUME;

static const buzzer_note_t *s_melody_notes;
static uint16_t             s_melody_count;
static uint16_t             s_melody_index;
static bool                 s_melody_repeat;
static bool                 s_melody_playing;
static buzzer_melody_done_cb s_melody_done_cb;

static struct k_work_delayable s_melody_work;

static void melody_step(struct k_work *work);
static void play_current_note(void);
static void timer_apply(void);

static void timer_apply(void)
{
    if (!device_is_ready(BUZZER_DEV)) {
        return;
    }

#if defined(CONFIG_PM_DEVICE)
    pm_device_action_run(BUZZER_DEV, PM_DEVICE_ACTION_RESUME);
#endif

    // 计算周期计数值 = 时钟频率 / 目标频率
    uint32_t period = BUZZER_TIMER_CLOCK_HZ / s_freq;
    if (period < 2U) {
        period = 2U;
    }

    uint8_t vol = s_volume_pct;
    if (vol > 100U) {
        vol = 100U;
    }
    // 满音量对应 50% 占空比 (获得最大差分驱动幅值)
    uint32_t pulse = (period * vol) / 200U;
    if (pulse < 1U) {
        pulse = 1U;
    }
    if (pulse >= period) {
        pulse = period - 1U;
    }

    pwm_set_cycles(BUZZER_DEV, BUZZER_CH_P, period, pulse, PWM_POLARITY_NORMAL);
    pwm_set_cycles(BUZZER_DEV, BUZZER_CH_N, period, pulse, PWM_POLARITY_INVERTED);
}

void buzzer_init(void)
{
    s_buzzer_on    = false;
    s_volume_pct   = BUZZER_DEFAULT_VOLUME;
    s_freq         = BUZZER_DEFAULT_FREQ;
    s_melody_playing = false;

    if (device_is_ready(BUZZER_DEV)) {
        pwm_set_cycles(BUZZER_DEV, BUZZER_CH_P, 0, 0, PWM_POLARITY_NORMAL);
        pwm_set_cycles(BUZZER_DEV, BUZZER_CH_N, 0, 0, PWM_POLARITY_NORMAL);
#if defined(CONFIG_PM_DEVICE)
        pm_device_action_run(BUZZER_DEV, PM_DEVICE_ACTION_SUSPEND);
#endif
    }

    k_work_init_delayable(&s_melody_work, melody_step);
}

void buzzer_on(void)
{
    if (s_buzzer_on) {
        return;
    }
    timer_apply();
    s_buzzer_on = true;
}

void buzzer_off(void)
{
    if (!s_buzzer_on) {
        return;
    }
    if (device_is_ready(BUZZER_DEV)) {
        // 关闭 PWM 输出: 两通道占空比清零并恢复 NORMAL 极性，
        // 保证 OUT0 (P0.13) 与 OUT1 (P0.14) 均拉低至 0V，避免静态直流漏电。
        pwm_set_cycles(BUZZER_DEV, BUZZER_CH_P, 0, 0, PWM_POLARITY_NORMAL);
        pwm_set_cycles(BUZZER_DEV, BUZZER_CH_N, 0, 0, PWM_POLARITY_NORMAL);

#if defined(CONFIG_PM_DEVICE)
        pm_device_action_run(BUZZER_DEV, PM_DEVICE_ACTION_SUSPEND);
#endif
    }
    s_buzzer_on = false;
}

bool buzzer_toggle(void)
{
    if (s_buzzer_on) {
        buzzer_off();
    } else {
        buzzer_on();
    }
    return s_buzzer_on;
}

bool buzzer_is_on(void)
{
    return s_buzzer_on;
}

void buzzer_set_volume(uint8_t volume_pct)
{
    if (volume_pct > 100U) {
        volume_pct = 100U;
    }
    s_volume_pct = volume_pct;
    if (s_buzzer_on) {
        timer_apply();
    }
}

static void play_current_note(void)
{
    while (s_melody_index < s_melody_count && s_melody_notes[s_melody_index].duration_ms == 0) {
        s_melody_index++;
    }

    if (s_melody_index >= s_melody_count) {
        if (s_melody_repeat && s_melody_count > 0) {
            s_melody_index = 0;
            while (s_melody_index < s_melody_count && s_melody_notes[s_melody_index].duration_ms == 0) {
                s_melody_index++;
            }
            if (s_melody_index >= s_melody_count) {
                s_melody_playing = false;
                buzzer_off();
                if (s_melody_done_cb) {
                    s_melody_done_cb(true);
                }
                return;
            }
        } else {
            s_melody_playing = false;
            buzzer_off();
            if (s_melody_done_cb) {
                s_melody_done_cb(true);
            }
            return;
        }
    }

    const buzzer_note_t *note = &s_melody_notes[s_melody_index];

    if (note->freq == 0) {
        buzzer_off();
    } else {
        if (note->freq != s_freq) {
            s_freq = note->freq;
            timer_apply();
        }
        if (!s_buzzer_on) {
            buzzer_on();
        }
    }

    k_work_reschedule(&s_melody_work, K_MSEC(note->duration_ms));
}

static void melody_step(struct k_work *work)
{
    (void)work;
    if (!s_melody_playing) {
        return;
    }

    s_melody_index++;
    play_current_note();
}

void buzzer_play_melody(const buzzer_note_t *notes, uint16_t count,
                        bool repeat, buzzer_melody_done_cb cb)
{
    if (!notes || count == 0) {
        return;
    }
    buzzer_stop_melody();

    s_melody_notes   = notes;
    s_melody_count   = count;
    s_melody_index   = 0;
    s_melody_repeat  = repeat;
    s_melody_done_cb = cb;
    s_melody_playing = true;

    play_current_note();
}

void buzzer_stop_melody(void)
{
    if (!s_melody_playing) {
        return;
    }
    k_work_cancel_delayable(&s_melody_work);
    s_melody_playing = false;
    buzzer_off();
    if (s_melody_done_cb) {
        s_melody_done_cb(false);
    }
}

bool buzzer_melody_is_playing(void)
{
    return s_melody_playing;
}
```

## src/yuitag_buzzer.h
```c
#ifndef YUITAG_BUZZER_H
#define YUITAG_BUZZER_H
// ============================================================
// YuiTag 蜂鸣器驱动 - 压电陶瓷差分推挽 PWM
// 平台: Nordic nRF52832 (Zephyr PWM 双通道互补输出)
// 基于 k_work_delayable 实现的非阻塞旋律播放引擎
// ============================================================

#include "yuitag_buzzer_types.h"

#endif // YUITAG_BUZZER_H
```

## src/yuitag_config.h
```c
#ifndef YUITAG_CONFIG_H
#define YUITAG_CONFIG_H

// ============================================================
// YuiTag Starlight (nRF52832) 平台配置
// 架构: nRF Connect SDK / Zephyr RTOS
// 版本: Starlight (支持 FindMy / ECDH 绑定 / OTA)
// ============================================================

#include <stdint.h>
#include <stddef.h>
#include <stdbool.h>

// ---- 编译期日志开关与输出宏 ----
#ifndef YUITAG_LOG_ENABLE
#define YUITAG_LOG_ENABLE  0
#endif

#if YUITAG_LOG_ENABLE
#include <zephyr/sys/printk.h>
#define platform_log(fmt, ...)  printk(fmt "\n", ##__VA_ARGS__)
#else
#define platform_log(fmt, ...)  ((void)0)
#endif

// ---- 固件与设备信息 ----
#define FW_VERSION         "1.0.0|NCS"
#define HW_VERSION         "V1|NRF52"
#define MANUFACTURER       "Yuitwork Labs 唯晴科技"
#define MODEL_NUMBER       "YuiTag Starlight|YLS05P"
#define DEVICE_NAME_PREFIX "YuiTag Starlight_"

// ---- 硬件射频发射功率边界 (dBm) ----
#ifndef HW_TX_POWER_MIN
#define HW_TX_POWER_MIN    (-40)   // nRF52 硬件支持最低发射功率 (dBm)
#endif
#ifndef HW_TX_POWER_MAX
#define HW_TX_POWER_MAX    4       // nRF52832 硬件支持最高发射功率 (dBm)
#endif


// ---- 引入跨平台公共协议常量 ----
#include "yuitag_config_common.h"

#endif // YUITAG_CONFIG_H
```

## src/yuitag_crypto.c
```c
// ============================================================
// YuiTag 平台密码学后端实现 - PSA Crypto (Oberon / nRF52832)
// 实现 yuitag_platform_api.h 声明的加密契约接口
// ============================================================

#include "yuitag_config.h"
#include "yuitag_platform_api.h"

#include <psa/crypto.h>
#include <zephyr/random/random.h>

#include <string.h>

static psa_key_id_t s_ecdhKeyId = 0;
static bool         s_ecdhReady = false;
static const uint8_t s_zeroNonce[16] = { 0 };

// ============================================================
// 加密模块生命周期
// ============================================================
void platform_crypto_init(void)
{
    psa_status_t status = psa_crypto_init();
    if (status != PSA_SUCCESS) {
        platform_log("[CRYPTO] psa_crypto_init failed: %d", status);
    }
    s_ecdhReady = false;
    s_ecdhKeyId = 0;
}

// ============================================================
// SHA-256
// ============================================================
bool platform_crypto_sha256(const uint8_t *in, size_t len, uint8_t out[32])
{
    size_t hashLen = 0;
    psa_status_t status = psa_hash_compute(PSA_ALG_SHA_256, in, len, out, 32, &hashLen);
    return (status == PSA_SUCCESS && hashLen == 32);
}

// ============================================================
// AES-128-CTR (零 IV)
// ============================================================
bool platform_crypto_aes128_ctr(const uint8_t key[16], const uint8_t *in, size_t len, uint8_t *out)
{
    if (len == 0) {
        return false;
    }

    psa_key_attributes_t attrs = PSA_KEY_ATTRIBUTES_INIT;
    psa_set_key_type(&attrs, PSA_KEY_TYPE_AES);
    psa_set_key_bits(&attrs, 128);
    psa_set_key_usage_flags(&attrs, PSA_KEY_USAGE_ENCRYPT | PSA_KEY_USAGE_DECRYPT);
    psa_set_key_algorithm(&attrs, PSA_ALG_CTR);

    psa_key_id_t key_id = 0;
    psa_status_t status = psa_import_key(&attrs, key, 16, &key_id);
    psa_reset_key_attributes(&attrs);
    if (status != PSA_SUCCESS) {
        return false;
    }

    psa_cipher_operation_t op = PSA_CIPHER_OPERATION_INIT;
    status = psa_cipher_encrypt_setup(&op, key_id, PSA_ALG_CTR);
    if (status != PSA_SUCCESS) {
        psa_destroy_key(key_id);
        return false;
    }

    status = psa_cipher_set_iv(&op, s_zeroNonce, sizeof(s_zeroNonce));
    if (status != PSA_SUCCESS) {
        psa_cipher_abort(&op);
        psa_destroy_key(key_id);
        return false;
    }

    size_t out_len = 0;
    status = psa_cipher_update(&op, in, len, out, len, &out_len);
    if (status != PSA_SUCCESS) {
        psa_cipher_abort(&op);
        psa_destroy_key(key_id);
        return false;
    }

    size_t finish_len = 0;
    status = psa_cipher_finish(&op, out + out_len, len - out_len, &finish_len);
    psa_destroy_key(key_id);
    return (status == PSA_SUCCESS);
}

// ============================================================
// 安全随机数
// ============================================================
void platform_crypto_random(uint8_t *buf, size_t len)
{
    psa_status_t status = psa_generate_random(buf, len);
    if (status != PSA_SUCCESS) {
        sys_csrand_get(buf, len);
    }
}

// ============================================================
// ECDH 密钥协商 (secp256r1)
// ============================================================
bool platform_ecdh_generate_keypair(void)
{
    if (s_ecdhReady && s_ecdhKeyId != 0) {
        psa_destroy_key(s_ecdhKeyId);
        s_ecdhKeyId = 0;
        s_ecdhReady = false;
    }

    psa_key_attributes_t attrs = PSA_KEY_ATTRIBUTES_INIT;
    psa_set_key_type(&attrs, PSA_KEY_TYPE_ECC_KEY_PAIR(PSA_ECC_FAMILY_SECP_R1));
    psa_set_key_bits(&attrs, 256);
    psa_set_key_usage_flags(&attrs, PSA_KEY_USAGE_DERIVE | PSA_KEY_USAGE_EXPORT);
    psa_set_key_algorithm(&attrs, PSA_ALG_ECDH);

    psa_status_t status = psa_generate_key(&attrs, &s_ecdhKeyId);
    psa_reset_key_attributes(&attrs);

    s_ecdhReady = (status == PSA_SUCCESS);
    return s_ecdhReady;
}

bool platform_ecdh_compute_shared(const uint8_t *peerPub, size_t len, uint8_t aesKeyOut[16])
{
    if (!s_ecdhReady) {
        return false;
    }

    uint8_t sharedSecret[ECDH_SHARED_SECRET_LEN];
    size_t secretLen = 0;

    psa_status_t status = psa_raw_key_agreement(PSA_ALG_ECDH,
                                                s_ecdhKeyId,
                                                peerPub, len,
                                                sharedSecret, sizeof(sharedSecret),
                                                &secretLen);
    if (status != PSA_SUCCESS) {
        memset(sharedSecret, 0, sizeof(sharedSecret));
        return false;
    }

    uint8_t kdfHash[SHA256_HASH_LEN];
    size_t hashLen = 0;
    psa_hash_compute(PSA_ALG_SHA_256, sharedSecret, secretLen,
                     kdfHash, sizeof(kdfHash), &hashLen);

    memcpy(aesKeyOut, kdfHash, 16);

    memset(sharedSecret, 0, sizeof(sharedSecret));
    memset(kdfHash, 0, sizeof(kdfHash));

    return true;
}

bool platform_ecdh_export_pubkey(uint8_t *out, size_t *outLen)
{
    if (!s_ecdhReady) {
        return false;
    }

    size_t exportedLen = 0;
    psa_status_t status = psa_export_public_key(s_ecdhKeyId,
                                                out, ECDH_PUBKEY_LEN,
                                                &exportedLen);
    if (status == PSA_SUCCESS) {
        *outLen = exportedLen;
        return true;
    }
    return false;
}

void platform_ecdh_cleanup(void)
{
    if (s_ecdhReady && s_ecdhKeyId != 0) {
        psa_destroy_key(s_ecdhKeyId);
        s_ecdhKeyId = 0;
    }
    s_ecdhReady = false;
}

bool platform_ecdh_ready(void)
{
    return s_ecdhReady;
}

// ============================================================
// Apple Find My ECC 密钥派生与公钥计算
// ============================================================
void platform_findmy_derive_seed(const uint8_t aesKey[16], uint8_t seedOut[32])
{
    uint8_t hash[SHA256_HASH_LEN];
    size_t hashLen = 0;
    psa_hash_compute(PSA_ALG_SHA_256, aesKey, 16, hash, sizeof(hash), &hashLen);
    memcpy(seedOut, hash, FINDMY_SEED_LEN);
    memset(hash, 0, sizeof(hash));
}

void platform_findmy_derive_private_key(const uint8_t seed[32],
                                         uint32_t period,
                                         uint8_t out[28])
{
    uint8_t input[FINDMY_SEED_LEN + 4 + FINDMY_DERIVE_INFO_LEN];
    uint8_t hash[SHA256_HASH_LEN];
    size_t hashLen = 0;

    memcpy(input, seed, FINDMY_SEED_LEN);
    input[FINDMY_SEED_LEN]     = (uint8_t)(period & 0xFF);
    input[FINDMY_SEED_LEN + 1] = (uint8_t)((period >> 8) & 0xFF);
    input[FINDMY_SEED_LEN + 2] = (uint8_t)((period >> 16) & 0xFF);
    input[FINDMY_SEED_LEN + 3] = (uint8_t)((period >> 24) & 0xFF);
    memcpy(input + FINDMY_SEED_LEN + 4, FINDMY_DERIVE_INFO, FINDMY_DERIVE_INFO_LEN);

    psa_hash_compute(PSA_ALG_SHA_256, input, sizeof(input), hash, sizeof(hash), &hashLen);
    memcpy(out, hash, FINDMY_KEY_LEN);

    memset(input, 0, sizeof(input));
    memset(hash, 0, sizeof(hash));
}

// secp224r1 曲线群阶 N (大端序, 28 字节)
static const uint8_t s_secp224r1_n[FINDMY_KEY_LEN] = {
    0xFF, 0xFF, 0xFF, 0xFF, 0xFF, 0xFF, 0xFF, 0xFF,
    0xFF, 0xFF, 0xFF, 0xFF, 0xFF, 0xFF, 0x16, 0xA2,
    0xE0, 0xB8, 0xF0, 0x3E, 0x13, 0xDD, 0x29, 0x45,
    0x5C, 0x5C, 0x2A, 0x3D
};

static void secp224r1_reduce_mod_n(const uint8_t in[FINDMY_KEY_LEN],
                                   uint8_t out[FINDMY_KEY_LEN])
{
    if (memcmp(in, s_secp224r1_n, FINDMY_KEY_LEN) >= 0) {
        int borrow = 0;
        for (int i = FINDMY_KEY_LEN - 1; i >= 0; i--) {
            int sub = (int)in[i] - (int)s_secp224r1_n[i] - borrow;
            if (sub < 0) {
                sub += 256;
                borrow = 1;
            } else {
                borrow = 0;
            }
            out[i] = (uint8_t)sub;
        }
    } else {
        memcpy(out, in, FINDMY_KEY_LEN);
    }
}

bool platform_findmy_compute_public_x(const uint8_t priv[28], uint8_t pubXOut[28])
{
    uint8_t reduced[FINDMY_KEY_LEN];
    secp224r1_reduce_mod_n(priv, reduced);

    psa_key_attributes_t attrs = PSA_KEY_ATTRIBUTES_INIT;
    psa_set_key_type(&attrs, PSA_KEY_TYPE_ECC_KEY_PAIR(PSA_ECC_FAMILY_SECP_R1));
    psa_set_key_bits(&attrs, 224);
    psa_set_key_usage_flags(&attrs, PSA_KEY_USAGE_EXPORT);
    psa_set_key_algorithm(&attrs, PSA_ALG_ECDH);

    psa_key_id_t key_id = 0;
    psa_status_t status = psa_import_key(&attrs, reduced, FINDMY_KEY_LEN, &key_id);
    psa_reset_key_attributes(&attrs);

    if (status != PSA_SUCCESS) {
        return false;
    }

    uint8_t pubkey[1 + 2 * FINDMY_KEY_LEN];
    size_t pubkey_len = 0;
    status = psa_export_public_key(key_id, pubkey, sizeof(pubkey), &pubkey_len);
    psa_destroy_key(key_id);

    if (status != PSA_SUCCESS || pubkey_len != sizeof(pubkey)) {
        return false;
    }

    memcpy(pubXOut, pubkey + 1, FINDMY_KEY_LEN);
    return true;
}
```

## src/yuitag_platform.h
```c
#ifndef YUITAG_PLATFORM_H
#define YUITAG_PLATFORM_H

// ============================================================
// YuiTag 平台驱动抽象 - Nordic nRF52832 / Zephyr
// 遵循 YuiTagCore 的 yuitag_platform_api.h 平台契约
// ============================================================

#include "yuitag_config.h"
#include "yuitag_platform_api.h"

void platform_init(void);

#endif // YUITAG_PLATFORM_H
```
